# STM32U375 register map
File version: 1.0
CPU: CM33 r0p1, little endian, MPU, FPU, 4 interrupt priority bits
Registers are 32-bit, read-write, reset 0x0 unless marked. A register's access mark holds for its fields unless they carry their own. Offsets are from the block's base; [hi:lo] are bit positions; {n}, {i} and the like mark numbered series; 'fields as' and 'values as' point back to an identical list.

## RCC — Habu_RCC register block
Base 0x40030C00
Same registers: SEC_RCC 0x50030C00
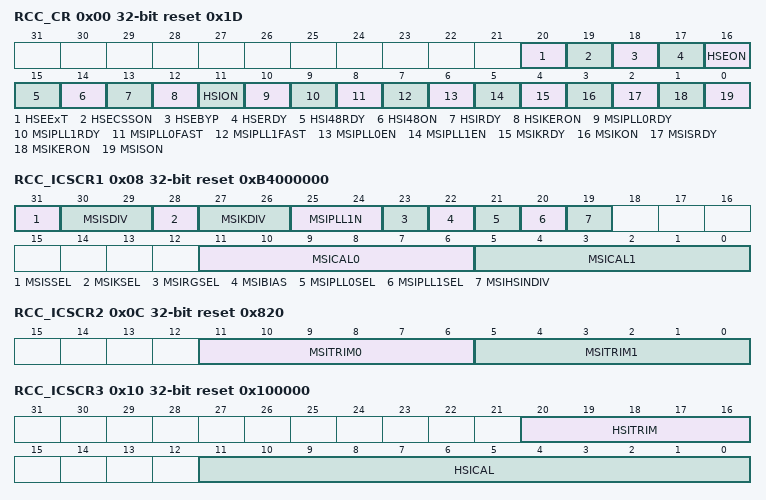
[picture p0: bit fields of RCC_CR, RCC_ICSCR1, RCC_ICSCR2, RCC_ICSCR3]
0x00 RCC_CR reset 0x1D — RCC clock control register
  [20] HSEExT — HSE external clock bypass mode
    0=External HSE clock analog mode; 1=External HSE clock digital mode (through I/O Schmitt trigger)
  [19] HSECSSON — Clock security system enable
    0=Clock security system OFF (clock detector OFF); 1=Clock security system ON (clock detector ON if the HSE oscillator is stable, OFF if not)
  [18] HSEBYP — HSE crystal oscillator bypass
    0=HSE crystal oscillator not bypassed; 1=HSE crystal oscillator bypassed with external clock
  [17] HSERDY ro — HSE clock ready flag
    0=HSE oscillator not ready; 1=HSE oscillator ready
  [16] HSEON — HSE clock enable
    0=HSE oscillator OFF; 1=HSE oscillator ON
  [15] HSI48RDY ro — HSI48 clock ready flag
    0=HSI48 oscillator not ready; 1=HSI48 oscillator ready
  [14] HSI48ON — HSI48 clock enable
    0=HSI48 oscillator OFF; 1=HSI48 oscillator ON
  [13] HSIRDY ro — HSI16 clock ready flag
    0=HSI16 oscillator not ready; 1=HSI16 oscillator ready
  [12] HSIKERON — HSI16 enable for some peripheral kernels
    0=No effect on HSI16 oscillator; 1=HSI16 oscillator forced ON even in Stop mode
  [11] HSION — HSI16 clock enable
    0=HSI16 oscillator OFF; 1=HSI16 oscillator ON
  [10] MSIPLL0RDY ro — MSIRC0 PLL mode ready flag
    0=MSIRC0 PLL mode is not ready; 1=MSIRC0 PLL mode is ready
  [9] MSIPLL1RDY ro — MSIRC1 PLL mode ready flag
    0=MSIRC1 PLL mode is not ready; 1=MSIRC1 PLL mode is ready
  [8] MSIPLL0FAST — MSIRC0 PLL mode fast startup
    0=MSIRC0 PLL normal startup; 1=MSIRC0 PLL fast startup
  [7] MSIPLL1FAST — MSIRC1 PLL mode fast startup
    0=MSIRC1 PLL normal startup; 1=MSIRC1 PLL fast startup
  [6] MSIPLL0EN — MSIRC0 PLL mode enable
    0=MSIRC0 PLL mode disabled; 1=MSIRC0 PLL mode enabled
  [5] MSIPLL1EN — MSIRC1 PLL mode enable
    0=MSIRC1 PLL mode disabled; 1=MSIRC1 PLL mode enabled
  [4] MSIKRDY ro — MSIK clock ready flag
    0=MSIK (MSI kernel) oscillator not ready; 1=MSIK (MSI kernel) oscillator ready
  [3] MSIKON — MSIK clock enable
    0=MSIK (MSI kernel) oscillator disabled; 1=MSIK (MSI kernel) oscillator enabled
  [2] MSISRDY ro — MSIS clock ready flag
    0=MSIS (MSI system) oscillator not ready; 1=MSIS (MSI system) oscillator ready
  [1] MSIKERON — MSI enable for some peripheral kernels
    0=No effect on MSI oscillator; 1=MSI oscillator forced ON even in Stop mode
  [0] MSISON — MSIS clock enable
    0=MSIS (MSI system) oscillator OFF; 1=MSIS (MSI system) oscillator ON
0x08 RCC_ICSCR1 reset 0xB4000000 (reset mask 0xFFFFF000) — RCC internal clock source calibration register 1
  [31] MSISSEL — MSIS clock source selection
    0=MSIRC0 (96 MHz) is selected as source to generate MSIS; 1=MSIRC1 (24 MHz) is selected as source to generate MSIS
  [30:29] MSISDIV — MSIS oscillator division
    0=B_0x0_MSISSEL_BIT_IN_RCC_ICSCR1__EQUAL_0 (MSIRC0/1 is selected for MSIS (range 0 around 96 MHz).); 1=B_0x1_MSISSEL_BIT_IN_RCC_ICSCR1__EQUAL_0 (MSIRC0/2 is selected for MSIS (range 1 around 48 MHz).); 2=B_0x2_MSISSEL_BIT_IN_RCC_ICSCR1__EQUAL_0 (MSIRC0/4 is selected for MSIS (range 2 around 24 MHz).); 3=B_0x3_MSISSEL_BIT_IN_RCC_ICSCR1__EQUAL_0 (MSIRC0/8 is selected for MSIS (range 3 around 12 MHz).)
  [28] MSIKSEL — MSIK clock source selection
    0=MSIRC0 (96 MHz) is selected as source to generate MSIK; 1=MSIRC1 (24 MHz) is selected as source to generate MSIK
  [27:26] MSIKDIV — MSIK oscillator division
    0=B_0x0_MSIKSEL_BIT_IN_RCC_ICSCR1__EQUAL_0 (MSIRC0/1 is selected for MSIK (range 0 around 96 MHz).); 1=B_0x1_MSIKSEL_BIT_IN_RCC_ICSCR1__EQUAL_0 (MSIRC0/2 is selected for MSIK (range 1 around 48 MHz).); 2=B_0x2_MSIKSEL_BIT_IN_RCC_ICSCR1__EQUAL_0 (MSIRC0/4 is selected for MSIK (range 2 around 24 MHz).); 3=B_0x3_MSIKSEL_BIT_IN_RCC_ICSCR1__EQUAL_0 (MSIRC0/8 is selected for MSIK (range 3 around 12 MHz).)
  [25:24] MSIPLL1N — MSIRC1 PLL mode with LSE multiplication factor
  [23] MSIRGSEL — MSI clock range selection
    0=MSIS/MSIK ranges provided by MSISDIVS[1:0] and MSIKDIVS[1:0] in RCC_CSR; 1=MSIS/MSIK ranges provided by MSISDIV[1:0] and MSIKDIV[1:0] in RCC_ICSCR1
  [22] MSIBIAS — MSI bias mode selection
    0=MSI bias continuous mode (clock accuracy fast settling time); 1=MSI bias sampling mode when the device is in Stop 1 or Stop 2 mode, or when the regulator is in range 2
  [21] MSIPLL0SEL — MSIRC0 PLL mode input clock selection
    0=LSE is used as MSIRC0 input clock when PLL mode is selected; 1=HSE or HSE/2 is used as MSIRC0 input clock when PLL mode is selected
  [20] MSIPLL1SEL — MSIRC1 PLL mode input clock selection
    0=LSE is used as MSIRC1 input clock when PLL mode is selected; 1=HSE or HSE/2 is used as MSIRC1 input clock when PLL mode is selected
  [19] MSIHSINDIV — MSIRCx (x = 0, 1) PLL mode HSE input division
    0=HSE (16 MHz) is used as MSI input clock when PLL mode with high-speed clock is selected; 1=HSE (32 MHz)/2 is used as MSI input clock when PLL mode with high-speed clock is selected
  [11:6] MSICAL0 ro — MSIRC0 clock calibration for MSI ranges 0 to 3
  [5:0] MSICAL1 ro — MSIRC1 clock calibration for MSI ranges 4 to 7
0x0C RCC_ICSCR2 reset 0x820 — RCC internal clock source calibration register 2
  [11:6] MSITRIM0 — MSIRC0 clock trimming for ranges 0 to 3
  [5:0] MSITRIM1 — MSIRC1 clock trimming for ranges 4 to 7
0x10 RCC_ICSCR3 reset 0x100000 (reset mask 0xFFFFF000) — RCC internal clock source calibration register 3
  [20:16] HSITRIM — HSI clock trimming
  [11:0] HSICAL ro — HSI clock calibration
0x14 RCC_CRRCR ro (reset mask 0xFFFFF000) — RCC clock recovery RC register
  [8:0] HSI48CAL — HSI48 clock calibration
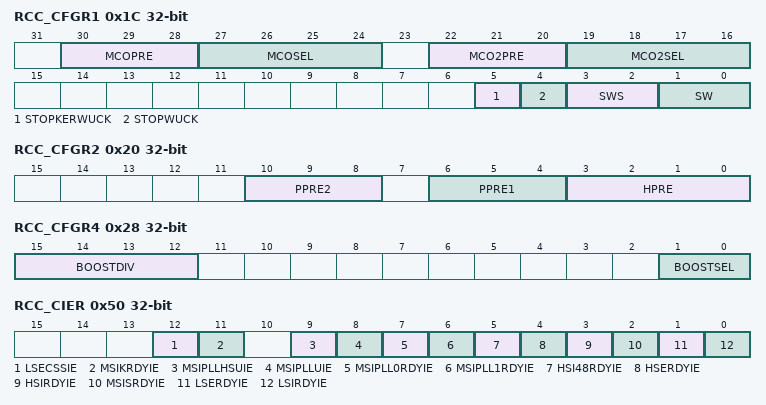
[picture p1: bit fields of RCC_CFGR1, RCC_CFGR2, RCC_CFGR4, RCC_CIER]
0x1C RCC_CFGR1 — RCC clock configuration register 1
  [30:28] MCOPRE — Microcontroller clock output prescaler
    0=MCO divided by 1; 1=MCO divided by 2; 2=MCO divided by 4; 3=MCO divided by 8; 4=MCO divided by 16; 5=MCO divided by 32; 6=MCO divided by 64; 7=MCO divided by 128
  [27:24] MCOSEL — Microcontroller clock output
    0=MCO output disabled, no clock on MCO; 1=SYSCLK system clock selected; 2=MSIS clock selected; 3=HSI16 clock selected; 4=HSE clock selected; 5=LSI clock selected; 6=LSE clock selected; 7=HSI48 clock selected; 8=MSIK clock selected
  [22:20] MCO2PRE — Microcontroller clock output 2 prescaler
    0=MCO2 divided by 1; 1=MCO2 divided by 2; 2=MCO2 divided by 4; 3=MCO2 divided by 8; 4=MCO2 divided by 16; 5=MCO2 divided by 32; 6=MCO2 divided by 64; 7=MCO2 divided by 128
  [19:16] MCO2SEL — Microcontroller clock output 2
    0=MCO2 output disabled, no clock on MCO2; 1=SYSCLK system clock selected; 2=MSIS clock selected; 3=HSI16 clock selected; 4=HSE clock selected 0101: LSI clock selected; 6=LSE clock selected; 7=HSI48 clock selected; 8=MSIK clock selected
  [5] STOPKERWUCK — Wake-up from Stop kernel clock automatic enable selection
    0=MSIK oscillator automatically enabled when exiting Stop mode or when a CSS on HSE event occurs; 1=HSI16 oscillator automatically enabled when exiting Stop mode or when a CSS on HSE event occurs
  [4] STOPWUCK — Wake-up from Stop and CSS backup clock selection
    0=MSIS oscillator selected as wake-up from stop clock and CSS backup clock; 1=HSI16 oscillator selected as wake-up from stop clock and CSS backup clock
  [3:2] SWS ro — System clock switch status
    0=MSIS oscillator used as system clock; 1=HSI16 oscillator used as system clock; 2=HSE used as system clock
  [1:0] SW — System clock switch
    0=MSIS selected as system clock; 1=HSI16 selected as system clock; 2=HSE selected as system clock
0x20 RCC_CFGR2 — RCC clock configuration register 2
  [10:8] PPRE2 — APB2 prescaler
    {v}=PCLK2 = HCLK not divided (v=0..3); 4=PCLK2 = HCLK divided by 2; 5=PCLK2 = HCLK divided by 4; 6=PCLK2 = HCLK divided by 8; 7=PCLK2 = HCLK divided by 16
  [6:4] PPRE1 — APB1 prescaler
    {v}=PCLK1 = HCLK not divided (v=0..3); 4=PCLK1 = HCLK divided by 2; 5=PCLK1 = HCLK divided by 4; 6=PCLK1 = HCLK divided by 8; 7=PCLK1 = HCLK divided by 16
  [3:0] HPRE — AHB prescaler
    {v}=HCLK = SYSCLK not divided (v=0..7); 8=HCLK = SYSCLK divided by 2; 9=HCLK = SYSCLK divided by 4; 10=HCLK = SYSCLK divided by 8; 11=HCLK = SYSCLK divided by 16; 12=HCLK = SYSCLK divided by 64; 13=HCLK = SYSCLK divided by 128; 14=HCLK = SYSCLK divided by 256; 15=HCLK = SYSCLK divided by 512
0x24 RCC_CFGR3 — RCC clock configuration register 3
  [6:4] PPRE3 — APB3 prescaler
    {v}=PCLK3 = HCLK not divided (v=0..3); 4=PCLK3 = HCLK divided by 2; 5=PCLK3 = HCLK divided by 4; 6=PCLK3 = HCLK divided by 8; 7=PCLK3 = HCLK divided by 16
0x28 RCC_CFGR4 — RCC clock configuration register 4
  [15:12] BOOSTDIV — EPOD booster input clock prescaler
    0=Divided by 1 (bypass); 1=Divided by 2; 2=Divided by 4; 3=Divided by 6; 4=Divided by 8; 5=Divided by 10; 6=Divided by 12; 7=Divided by 14; 8=Divided by 16
  [1:0] BOOSTSEL — EPOD booster input clock source selection
    0=No clock; 1=MSIS selected as EPOD booster clock source; 2=HSI16 selected as EPOD booster clock source; 3=HSE selected as EPOD booster clock source
0x50 RCC_CIER — RCC clock interrupt enable register
  [12] LSECSSIE — LSE clock security system interrupt enable
    0=LSE CSS interrupt disabled; 1=LSE CSS interrupt enabled
  [11] MSIKRDYIE — MSIK ready interrupt enable
    0=MSIK ready interrupt disabled; 1=MSIK ready interrupt enabled
  [9] MSIPLLHSUIE — MSI PLL mode with HSE unlock interrupt enable
    0=MSI PLL mode with HSE unlock interrupt disabled; 1=MSI PLL mode with HSE unlock interrupt enabled
  [8] MSIPLLUIE — MSI PLL mode with LSE unlock interrupt enable
    0=MSI PLL mode with LSE unlock interrupt disabled; 1=MSI PLL mode with LSE unlock interrupt enabled
  [7] MSIPLL0RDYIE — MSIRC0 PLL mode ready interrupt enable
    0=MSIRC0 PLL mode lock interrupt disabled; 1=MSIRC0 PLL mode lock interrupt enabled
  [6] MSIPLL1RDYIE — MSIRC1 PLL mode ready interrupt enable
    0=MSIRC1 PLL mode lock interrupt disabled; 1=MSIRC1 PLL mode lock interrupt enabled
  [5] HSI48RDYIE — HSI48 ready interrupt enable
    0=HSI48 ready interrupt disabled; 1=HSI48 ready interrupt enabled
  [4] HSERDYIE — HSE ready interrupt enable
    0=HSE ready interrupt disabled; 1=HSE ready interrupt enabled
  [3] HSIRDYIE — HSI16 ready interrupt enable
    0=HSI16 ready interrupt disabled; 1=HSI16 ready interrupt enabled
  [2] MSISRDYIE — MSIS ready interrupt enable
    0=MSIS ready interrupt disabled; 1=MSIS ready interrupt enabled
  [1] LSERDYIE — LSE ready interrupt enable
    0=LSE ready interrupt disabled; 1=LSE ready interrupt enabled
  [0] LSIRDYIE — LSI ready interrupt enable
    0=LSI ready interrupt disabled; 1=LSI ready interrupt enabled
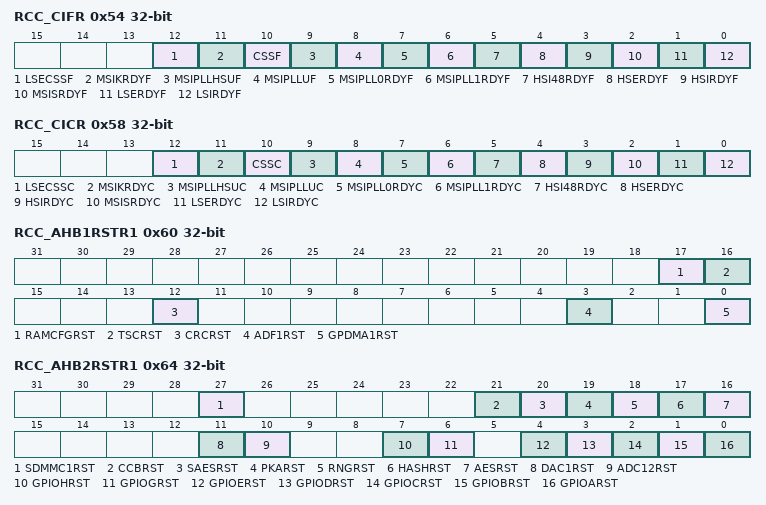
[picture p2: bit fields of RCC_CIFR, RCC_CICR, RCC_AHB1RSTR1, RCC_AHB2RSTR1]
0x54 RCC_CIFR ro — RCC clock interrupt flag register
  [12] LSECSSF — LSE clock security system interrupt flag
    0=No LSE clock security interrupt; 1=LSE clock security interrupt
  [11] MSIKRDYF — MSIK ready interrupt flag
    0=No MSIK oscillator clock ready interrupt; 1=MSIK oscillator clock ready interrupt
  [10] CSSF — Clock security system interrupt flag
    0=No HSE clock security interrupt; 1=HSE clock security interrupt
  [9] MSIPLLHSUF — MSI PLL mode with HSE unlock interrupt flag
    0=No MSI PLL mode with HSE unlock interrupt; 1=MSI PLL mode with HSE unlock interrupt
  [8] MSIPLLUF — MSI PLL mode with LSE unlock interrupt flag
    0=No MSI PLL mode with LSE unlock interrupt; 1=MSI PLL mode with LSE unlock interrupt
  [7] MSIPLL0RDYF — MSIRC0 PLL mode ready interrupt flag
    0=No MSIRC0 PLL mode ready interrupt; 1=MSIRC0 PLL mode ready interrupt
  [6] MSIPLL1RDYF — MSIRC1 PLL mode ready interrupt enable
    0=No MSIRC1 PLL mode ready interrupt; 1=MSIRC1 PLL mode ready interrupt
  [5] HSI48RDYF — HSI48 ready interrupt flag
    0=No HSI48 ready interrupt; 1=HSI48 ready interrupt
  [4] HSERDYF — HSE ready interrupt flag
    0=No HSE ready interrupt; 1=HSE ready interrupt
  [3] HSIRDYF — HSI16 ready interrupt flag
    0=No HSI16 ready interrupt; 1=HSI16 ready interrupt
  [2] MSISRDYF — MSIS ready interrupt flag
    0=No MSIS ready interrupt; 1=MSIS ready interrupt
  [1] LSERDYF — LSE ready interrupt flag
    0=No LSE ready interrupt; 1=LSE ready interrupt
  [0] LSIRDYF — LSI ready interrupt flag
    0=No LSI ready interrupt; 1=LSI ready interrupt
0x58 RCC_CICR wo — RCC clock interrupt clear register
  [12] LSECSSC — LSE CSS interrupt clear
  [11] MSIKRDYC — MSIK oscillator ready interrupt clear
  [10] CSSC — Clock security system interrupt clear
  [9] MSIPLLHSUC — MSI PLL mode with HSE unlock interrupt clear
  [8] MSIPLLUC — MSI PLL mode with LSE unlock interrupt clear
  [7] MSIPLL0RDYC — MSIRC0 PLL mode ready interrupt clear
  [6] MSIPLL1RDYC — MSIRC1 PLL mode ready interrupt clear
  [5] HSI48RDYC — HSI48 ready interrupt clear
  [4] HSERDYC — HSE ready interrupt clear
  [3] HSIRDYC — HSI16 ready interrupt clear
  [2] MSISRDYC — MSIS ready interrupt clear
  [1] LSERDYC — LSE ready interrupt clear
  [0] LSIRDYC — LSI ready interrupt clear
0x60 RCC_AHB1RSTR1 — RCC AHB1 peripheral reset register 1
  [17] RAMCFGRST — RAMCFG reset
    0=No effect; 1=Reset RAMCFG
  [16] TSCRST — TSC reset
    0=No effect; 1=Reset TSC
  [12] CRCRST — CRC reset
    0=No effect; 1=Reset CRC
  [3] ADF1RST — ADF1 reset
    0=No effect; 1=Reset ADF1
  [0] GPDMA1RST — GPDMA1 reset
    0=No effect; 1=Reset GPDMA1
0x64 RCC_AHB2RSTR1 — RCC AHB2 peripheral reset register 1
  [27] SDMMC1RST — SDMMC1 reset
    0=No effect; 1=Reset SDMMC1
  [21] CCBRST — CCB reset
    0=No effect; 1=Reset CCB
  [20] SAESRST — SAES hardware accelerator reset
    0=No effect; 1=Reset SAES
  [19] PKARST — PKA reset
    0=No effect; 1=Reset PKA
  [18] RNGRST — Random number generator reset
    0=No effect; 1=Reset RNG
  [17] HASHRST — HASH reset
    0=No effect; 1=Reset HASH
  [16] AESRST — AES hardware accelerator reset
    0=No effect; 1=Reset AES
  [11] DAC1RST — DAC1 reset
    0=No effect; 1=Reset DAC1
  [10] ADC12RST — ADC12 reset
    0=No effect; 1=Reset ADC12
  [7] GPIOHRST — I/O port i reset (i = H to G)
    0=No effect; 1=Reset I/O port i
  [6] GPIOGRST — I/O port i reset (i = H to G)
    0=No effect; 1=Reset I/O port i
  [4] GPIOERST — I/O port i reset (i = E to A)
    0=No effect; 1=Reset I/O port i
  [3] GPIODRST — I/O port i reset (i = E to A)
    0=No effect; 1=Reset I/O port i
  [2] GPIOCRST — I/O port i reset (i = E to A)
    0=No effect; 1=Reset I/O port i
  [1] GPIOBRST — I/O port i reset (i = E to A)
    0=No effect; 1=Reset I/O port i
  [0] GPIOARST — I/O port i reset (i = E to A)
    0=No effect; 1=Reset I/O port i
0x68 RCC_AHB2RSTR2 — RCC AHB2 peripheral reset register 2
  [4] OCTOSPI1RST — OCTOSPI1 reset
    0=No effect; 1=Reset OCTOSPI1
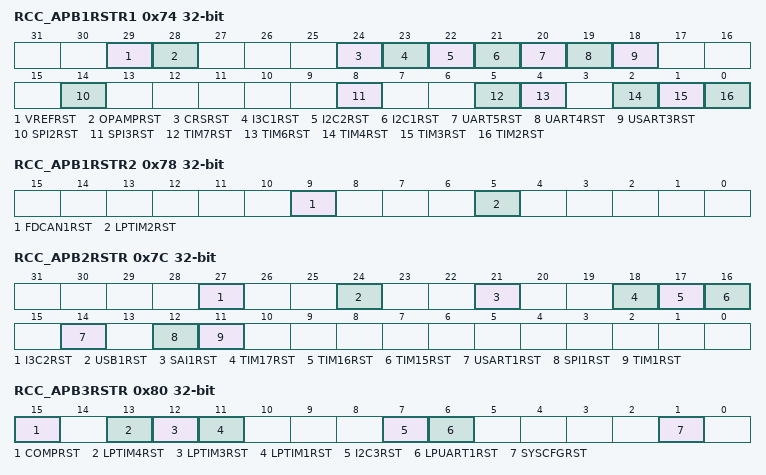
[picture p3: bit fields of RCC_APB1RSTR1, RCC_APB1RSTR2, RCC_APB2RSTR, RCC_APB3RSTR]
0x74 RCC_APB1RSTR1 — RCC APB1 peripheral reset register 1
  [29] VREFRST — VREFBUF reset
    0=No effect; 1=Reset VREFBUF
  [28] OPAMPRST — OPAMP reset
    0=No effect; 1=Reset OPAMP
  [24] CRSRST — CRS reset
    0=No effect; 1=Reset the CRS
  [23] I3C1RST — I3C1 reset
    0=No effect; 1=Reset the I3C1
  [22] I2C2RST — I2C2 reset
    0=No effect; 1=Reset the I2C2
  [21] I2C1RST — I2C1 reset
    0=No effect; 1=Reset the I2C1
  [20] UART5RST — UART5 reset
    0=No effect; 1=Reset UART5
  [19] UART4RST — UART4 reset
    0=No effect; 1=Reset UART4
  [18] USART3RST — USART3 reset
    0=No effect; 1=Reset USART3
  [14] SPI2RST — SPI2 reset
    0=No effect; 1=Reset SPI2
  [8] SPI3RST — SPI3 reset
    0=No effect; 1=Reset SPI3
  [5] TIM7RST — TIMj reset
    0=No effect; 1=Reset TIMj
  [4] TIM6RST — TIMj reset
    0=No effect; 1=Reset TIMj
  [2] TIM4RST — TIMj reset
    0=No effect; 1=Reset TIMj
  [1] TIM3RST — TIMj reset
    0=No effect; 1=Reset TIMj
  [0] TIM2RST — TIMj reset
    0=No effect; 1=Reset TIMj
0x78 RCC_APB1RSTR2 — RCC APB1 peripheral reset register 2
  [9] FDCAN1RST — FDCAN1 reset
    0=No effect; 1=Reset FDCAN1
  [5] LPTIM2RST — LPTIM2 reset
    0=No effect; 1=Reset LPTIM2
0x7C RCC_APB2RSTR — RCC APB2 peripheral reset register
  [27] I3C2RST — I3C2 reset
    0=No effect; 1=Reset I3C2
  [24] USB1RST — USB1 reset
    0=No effect; 1=Reset USB1
  [21] SAI1RST — SAI1 reset
    0=No effect; 1=Reset SAI1
  [18] TIM17RST — TIMi reset
    0=No effect; 1=Reset TIMi
  [17] TIM16RST — TIMi reset
    0=No effect; 1=Reset TIMi
  [16] TIM15RST — TIMi reset
    0=No effect; 1=Reset TIMi
  [14] USART1RST — USART1 reset
    0=No effect; 1=Reset USART1
  [12] SPI1RST — SPI1 reset
    0=No effect; 1=Reset SPI1
  [11] TIM1RST — TIM1 reset
    0=No effect; 1=Reset TIM1
0x80 RCC_APB3RSTR — RCC APB3 peripheral reset register
  [15] COMPRST — COMP reset
    0=No effect; 1=Reset COMP
  [13] LPTIM4RST — LPTIMi reset
    0=No effect; 1=Reset LPTIMi
  [12] LPTIM3RST — LPTIMi reset
    0=No effect; 1=Reset LPTIMi
  [11] LPTIM1RST — LPTIM1 reset
    0=No effect; 1=Reset LPTIM1
  [7] I2C3RST — I2C3 reset
    0=No effect; 1=Reset I2C3
  [6] LPUART1RST — LPUART1 reset
    0=No effect; 1=Reset LPUART1
  [1] SYSCFGRST — SYSCFG reset
    0=No effect; 1=Reset SYSCFG
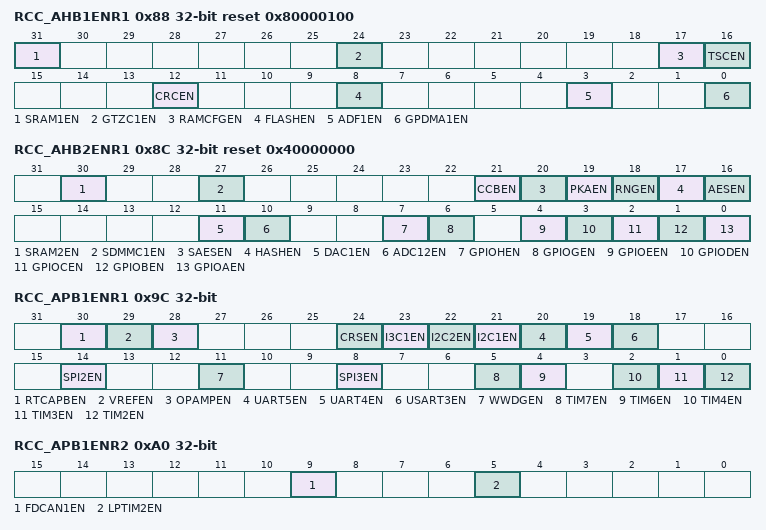
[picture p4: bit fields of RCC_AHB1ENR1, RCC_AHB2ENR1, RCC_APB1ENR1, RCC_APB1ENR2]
0x88 RCC_AHB1ENR1 reset 0x80000100 — RCC AHB1 peripheral clock enable register 1
  [31] SRAM1EN — SRAM1 clock enable
    0=SRAM1 clock disabled; 1=SRAM1 clock enabled
  [24] GTZC1EN — GTZC1 clock enable
    0=GTZC1 clock disabled; 1=GTZC1 clock enabled
  [17] RAMCFGEN — RAMCFG clock enable
    0=RAMCFG clock disabled; 1=RAMCFG clock enabled
  [16] TSCEN — Touch sensing controller clock enable
    0=TSC clock disabled; 1=TSC clock enabled
  [12] CRCEN — CRC clock enable
    0=CRC clock disabled; 1=CRC clock enabled
  [8] FLASHEN — FLASH clock enable
    0=FLASH clock disabled; 1=FLASH clock enabled
  [3] ADF1EN — ADF1 clock enable
    0=ADF1 clock disabled; 1=ADF1 clock enabled
  [0] GPDMA1EN — GPDMA1 clock enable
    0=GPDMA1 clock disabled; 1=GPDMA1 clock enabled
0x8C RCC_AHB2ENR1 reset 0x40000000 — RCC AHB2 peripheral clock enable register 1
  [30] SRAM2EN — SRAM2 clock enable
    0=SRAM2 clock disabled; 1=SRAM2 clock enabled
  [27] SDMMC1EN — SDMMC1 clock enable
    0=SDMMC1 clock disabled; 1=SDMMC1 clock enabled
  [21] CCBEN — CCB clock enable
    0=CCB clock disabled; 1=CCB clock enabled
  [20] SAESEN — SAES clock enable
    0=SAES clock disabled; 1=SAES clock enabled
  [19] PKAEN — PKA clock enable
    0=PKA clock disabled; 1=PKA clock enabled
  [18] RNGEN — RNG clock enable
    0=RNG clock disabled; 1=RNG clock enabled
  [17] HASHEN — HASH clock enable
    0=HASH clock disabled; 1=HASH clock enabled
  [16] AESEN — AES clock enable
    0=AES clock disabled; 1=AES clock enabled
  [11] DAC1EN — DAC1 clock enable
    0=DAC1 clock disabled; 1=DAC1 clock enabled
  [10] ADC12EN — ADC12 clock enable
    0=ADC12 clock disabled; 1=ADC12 clock enabled
  [7] GPIOHEN — I/O port i clock enable (i = H to G)
    0=I/O port i clock disabled; 1=I/O port i clock enabled
  [6] GPIOGEN — I/O port i clock enable (i = H to G)
    0=I/O port i clock disabled; 1=I/O port i clock enabled
  [4] GPIOEEN — I/O port i clock enable (i = E to A)
    0=I/O port i clock disabled; 1=I/O port i clock enabled
  [3] GPIODEN — I/O port i clock enable (i = E to A)
    0=I/O port i clock disabled; 1=I/O port i clock enabled
  [2] GPIOCEN — I/O port i clock enable (i = E to A)
    0=I/O port i clock disabled; 1=I/O port i clock enabled
  [1] GPIOBEN — I/O port i clock enable (i = E to A)
    0=I/O port i clock disabled; 1=I/O port i clock enabled
  [0] GPIOAEN — I/O port i clock enable (i = E to A)
    0=I/O port i clock disabled; 1=I/O port i clock enabled
0x90 RCC_AHB2ENR2 — RCC AHB2 peripheral clock enable register 2
  [4] OCTOSPI1EN — OCTOSPI1 clock enable
    0=OCTOSPI1 clock disabled; 1=OCTOSPI1 clock enabled
0x94 RCC_AHB1ENR2 — RCC AHB1 peripheral clock enable register 2
  [2] PWREN — PWR clock enable
    0=PWR clock disabled; 1=PWR clock enabled
0x9C RCC_APB1ENR1 — RCC APB1 peripheral clock enable register 1
  [30] RTCAPBEN — RTC and TAMP APB clock enable
    0=RTC and TAMP APB clock disabled; 1=RTC and TAMP APB clock enabled
  [29] VREFEN — VREFBUF clock enable
    0=VREFBUF clock disabled; 1=VREFBUF clock enabled
  [28] OPAMPEN — OPAMP clock enable
    0=OPAMP clock disabled; 1=OPAMP clock enabled
  [24] CRSEN — CRS clock enable
    0=CRS clock disabled; 1=CRS clock enabled
  [23] I3C1EN — I3C1 clock enable
    0=I3C1 clock disabled; 1=I3C1 clock enabled
  [22] I2C2EN — I2C2 clock enable
    0=I2C2 clock disabled; 1=I2C2 clock enabled
  [21] I2C1EN — I2C1 clock enable
    0=I2C1 clock disabled; 1=I2C1 clock enabled
  [20] UART5EN — UART5 clock enable
    0=UART5 clocks disabled; 1=UART5 clock enabled
  [19] UART4EN — UART4 clock enable
    0=UART4 clocks disabled; 1=UART4 clock enabled
  [18] USART3EN — USART3 clock enable
    0=USART3 clocks disabled; 1=USART3 clock enabled
  [14] SPI2EN — SPI2 clock enable
    0=SPI2 clock disabled; 1=SPI2 clock enabled
  [11] WWDGEN — WWDG clock enable
    0=WWDG clock disabled; 1=WWDG clock enabled
  [8] SPI3EN — SPI3 clock enable
    0=SPI3 clock disabled; 1=SPI3 clock enabled
  [5] TIM7EN — TIMj clock enable
    0=TIMj clock disabled; 1=TIMj clock enabled
  [4] TIM6EN — TIMj clock enable
    0=TIMj clock disabled; 1=TIMj clock enabled
  [2] TIM4EN — TIMj clock enable
    0=TIMj clock disabled; 1=TIMj clock enabled
  [1] TIM3EN — TIMj clock enable
    0=TIMj clock disabled; 1=TIMj clock enabled
  [0] TIM2EN — TIMj clock enable
    0=TIMj clock disabled; 1=TIMj clock enabled
0xA0 RCC_APB1ENR2 — RCC APB1 peripheral clock enable register 2
  [9] FDCAN1EN — FDCAN1 clock enable
    0=FDCAN1 clock disabled; 1=FDCAN1 clock enabled
  [5] LPTIM2EN — LPTIM2 clock enable
    0=LPTIM2 clock disabled; 1=LPTIM2 clock enabled
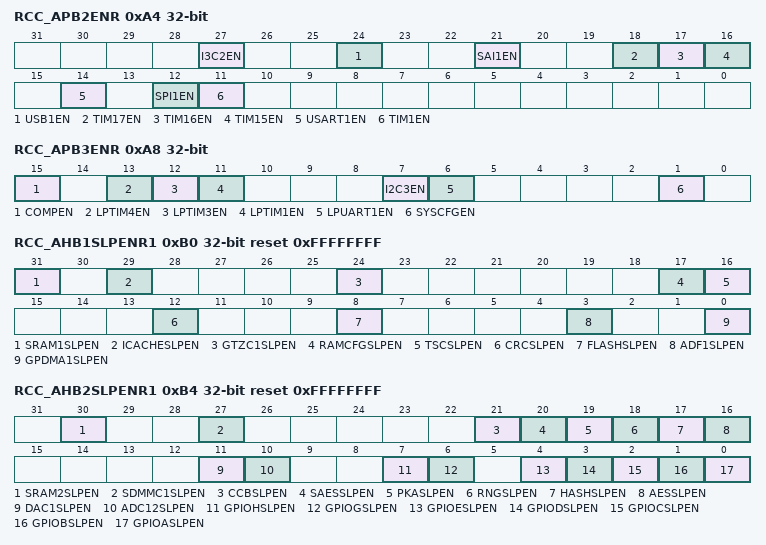
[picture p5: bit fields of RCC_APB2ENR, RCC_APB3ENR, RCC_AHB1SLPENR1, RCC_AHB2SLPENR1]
0xA4 RCC_APB2ENR — RCC APB2 peripheral clock enable register
  [27] I3C2EN — I3C2 clock enable
    0=I3C2 clock disabled; 1=I3C2 clock enabled
  [24] USB1EN — USB1 clock enable
    0=USB1 clock disabled; 1=USB1 clock enabled
  [21] SAI1EN — SAI1 clock enable
    0=SAI1 clock disabled; 1=SAI1 clock enabled
  [18] TIM17EN — TIMi clock enable
    0=TIMi clock disabled; 1=TIMi clock enabled
  [17] TIM16EN — TIMi clock enable
    0=TIMi clock disabled; 1=TIMi clock enabled
  [16] TIM15EN — TIMi clock enable
    0=TIMi clock disabled; 1=TIMi clock enabled
  [14] USART1EN — USART1clock enable
    0=USART1 clock disabled; 1=USART1 clock enabled
  [12] SPI1EN — SPI1 clock enable
    0=SPI1 clock disabled; 1=SPI1 clock enabled
  [11] TIM1EN — TIM1 clock enable
    0=TIM1 clock disabled; 1=TIM1 clock enabled
0xA8 RCC_APB3ENR — RCC APB3 peripheral clock enable register
  [15] COMPEN — COMP clock enable
    0=COMP clock disabled; 1=COMP clock enabled
  [13] LPTIM4EN — LPTIMi clock enable
    0=LPTIMi clock disabled; 1=LPTIMi clock enabled
  [12] LPTIM3EN — LPTIMi clock enable
    0=LPTIMi clock disabled; 1=LPTIMi clock enabled
  [11] LPTIM1EN — LPTIM1 clock enable
    0=LPTIM1 clock disabled; 1=LPTIM1 clock enabled
  [7] I2C3EN — I2C3 clock enable
    0=I2C3 clock disabled; 1=I2C3 clock enabled
  [6] LPUART1EN — LPUART1 clock enable
    0=LPUART1 clock disabled; 1=LPUART1 clock enabled
  [1] SYSCFGEN — SYSCFG clock enable
    0=SYSCFG clock disabled; 1=SYSCFG clock enabled
0xB0 RCC_AHB1SLPENR1 reset 0xFFFFFFFF — RCC AHB1 peripheral clock enable in Sleep mode register
  [31] SRAM1SLPEN — SRAM1 clock enable during Sleep mode
    0=SRAM1 clocks disabled by the clock gating during Sleep mode; 1=SRAM1 clock enabled by the clock gating during Sleep mode
  [29] ICACHESLPEN — ICACHE clock enable during Sleep mode
    0=ICACHE clocks disabled by the clock gating during Sleep mode; 1=ICACHE clock enabled by the clock gating during Sleep mode
  [24] GTZC1SLPEN — GTZC1 clock enable during Sleep mode
    0=GTZC1 clocks disabled by the clock gating during Sleep mode; 1=GTZC1 clock enabled by the clock gating during Sleep mode
  [17] RAMCFGSLPEN — RAMCFG clock enable during Sleep mode
    0=RAMCFG clocks disabled by the clock gating during Sleep mode; 1=RAMCFG clock enabled by the clock gating during Sleep mode
  [16] TSCSLPEN — TSC clock enable during Sleep mode
    0=TSC clocks disabled by the clock gating during Sleep mode; 1=TSC clock enabled by the clock gating during Sleep mode
  [12] CRCSLPEN — CRC clock enable during Sleep mode
    0=CRC clocks disabled by the clock gating during Sleep mode; 1=CRC clock enabled by the clock gating during Sleep mode
  [8] FLASHSLPEN — FLASH clock enable during Sleep mode
    0=FLASH clocks disabled by the clock gating during Sleep mode; 1=FLASH clock enabled by the clock gating during Sleep mode
  [3] ADF1SLPEN — ADF1 clock enable during Sleep mode.
    0=ADF1 clocks disabled by the clock gating during Sleep mode; 1=ADF1 clock enabled by the clock gating during Sleep mode
  [0] GPDMA1SLPEN — GPDMA1 clock enable during Sleep mode
    0=GPDMA1 clocks disabled by the clock gating during Sleep mode; 1=GPDMA1 clock enabled by the clock gating during Sleep mode
0xB4 RCC_AHB2SLPENR1 reset 0xFFFFFFFF — RCC AHB2 peripheral clock enable in Sleep mode register 1
  [30] SRAM2SLPEN — SRAM2 clock enable during Sleep mode
    0=SRAM2 clocks disabled by the clock gating during Sleep mode; 1=SRAM2 clock enabled by the clock gating during Sleep mode
  [27] SDMMC1SLPEN — SDMMC1 clock enable during Sleep mode
    0=SDMMC1 clocks disabled by the clock gating during Sleep mode; 1=SDMMC1 clock enabled by the clock gating during Sleep mode
  [21] CCBSLPEN — CCB accelerator clock enable during Sleep mode
    0=CCB clocks disabled by the clock gating during Sleep mode; 1=CCB clock enabled by the clock gating during Sleep mode
  [20] SAESSLPEN — SAES accelerator clock enable during Sleep mode
    0=SAES clocks disabled by the clock gating during Sleep mode; 1=SAES clock enabled by the clock gating during Sleep mode
  [19] PKASLPEN — PKA clock enable during Sleep mode
    0=PKA clocks disabled by the clock gating during Sleep mode; 1=PKA clock enabled by the clock gating during Sleep mode
  [18] RNGSLPEN — RNG clock enable during Sleep mode
    0=RNG clocks disabled by the clock gating during Sleep mode; 1=RNG clock enabled by the clock gating during Sleep mode
  [17] HASHSLPEN — HASH clock enable during Sleep mode
    0=HASH clocks disabled by the clock gating during Sleep mode; 1=HASH clock enabled by the clock gating during Sleep mode
  [16] AESSLPEN — AES clock enable during Sleep mode
    0=AES clocks disabled by the clock gating during Sleep mode; 1=AES clock enabled by the clock gating during Sleep mode
  [11] DAC1SLPEN — DAC1 clock enable during Sleep mode
    0=DAC1 clocks disabled by the clock gating during Sleep mode; 1=DAC1 clock enabled by the clock gating during Sleep mode
  [10] ADC12SLPEN — ADC12 clock enable during Sleep mode
    0=ADC12 clocks disabled by the clock gating during Sleep mode; 1=ADC12 clock enabled by the clock gating during Sleep mode
  [7] GPIOHSLPEN — I/O port i clock enable during Sleep mode (i = H to G)
    0=I/O port i clocks disabled by the clock gating during Sleep mode; 1=I/O port i clock enabled by the clock gating during Sleep mode
  [6] GPIOGSLPEN — I/O port i clock enable during Sleep mode (i = H to G)
    values as GPIOHSLPEN
  [4] GPIOESLPEN — I/O port i clock enable during Sleep mode (i = E to A)
    values as GPIOHSLPEN
  [3] GPIODSLPEN — I/O port i clock enable during Sleep mode (i = E to A)
    values as GPIOHSLPEN
  [2] GPIOCSLPEN — I/O port i clock enable during Sleep mode (i = E to A)
    values as GPIOHSLPEN
  [1] GPIOBSLPEN — I/O port i clock enable during Sleep mode (i = E to A)
    values as GPIOHSLPEN
  [0] GPIOASLPEN — I/O port i clock enable during Sleep mode (i = E to A)
    values as GPIOHSLPEN
0xB8 RCC_AHB2SLPENR2 reset 0xFFFFFFFF — RCC AHB2 peripheral clock enable in Sleep mode register 2
  [4] OCTOSPI1SLPEN — OCTOSPI1 clock enable during Sleep mode
    0=OCTOSPI1 clocks disabled by the clock gating during Sleep mode; 1=OCTOSPI1 clock enabled by the clock gating during Sleep mode
0xBC RCC_AHB1SLPENR2 reset 0xFFFFFFFF — RCC AHB1 peripheral clock enable in Sleep mode register 2
  [2] PWRSLPEN — PWR clock enable during Sleep mode
    0=PWR clock disabled by the clock gating during Sleep mode; 1=PWR clock enabled by the clock gating during Sleep mode
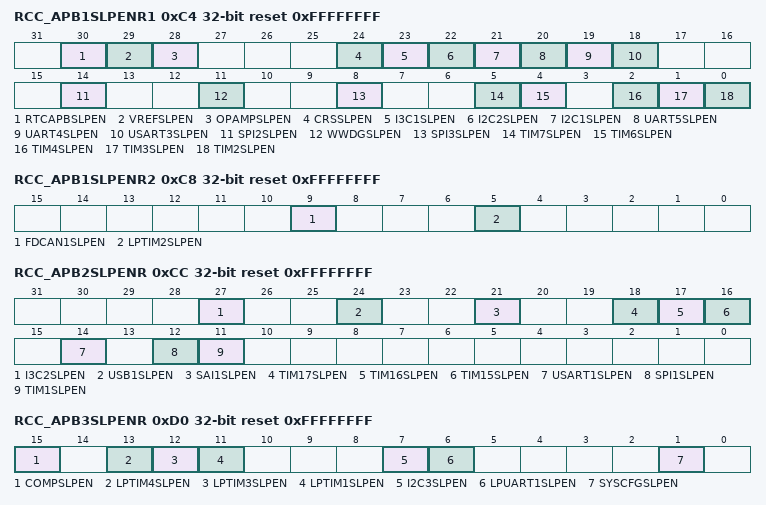
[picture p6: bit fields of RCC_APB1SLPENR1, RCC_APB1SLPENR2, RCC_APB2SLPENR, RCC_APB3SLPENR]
0xC4 RCC_APB1SLPENR1 reset 0xFFFFFFFF — RCC APB1 peripheral clock enable in Sleep mode register 1
  [30] RTCAPBSLPEN — RTC and TAMP APB clock enable during Sleep mode
    0=RTC and TAMP APB clock disabled by the clock gating during Sleep mode; 1=RTC and TAMP APB clock enabled by the clock gating during Sleep mode
  [29] VREFSLPEN — VREFBUF clock enable during Sleep mode
    0=VREFBUF clocks disabled by the clock gating during Sleep mode; 1=VREFBUF clock enabled by the clock gating during Sleep mode
  [28] OPAMPSLPEN — OPAMP clock enable during Sleep mode
    0=OPAMP clocks disabled by the clock gating during Sleep mode; 1=OPAMP clock enabled by the clock gating during Sleep mode
  [24] CRSSLPEN — CRS clock enable during Sleep mode
    0=CRS clocks disabled by the clock gating during Sleep mode; 1=CRS clock enabled by the clock gating during Sleep mode
  [23] I3C1SLPEN — I3C1 clock enable during Sleep mode
    0=I3C1 clocks disabled by the clock gating during Sleep mode; 1=I3C1 clock enabled by the clock gating during Sleep mode
  [22] I2C2SLPEN — I2C2 clock enable during Sleep mode
    0=I2C2 clocks disabled by the clock gating during Sleep mode; 1=I2C2 clock enabled by the clock gating during Sleep mode
  [21] I2C1SLPEN — I2C1 clock enable during Sleep mode
    0=I2C1 clocks disabled by the clock gating during Sleep mode; 1=I2C1 clock enabled by the clock gating during Sleep mode
  [20] UART5SLPEN — UART5 clock enable during Sleep mode
    0=UART5 clocks disabled by the clock gating during Sleep mode; 1=UART5 clock enabled by the clock gating during Sleep mode
  [19] UART4SLPEN — UART4 clock enable during Sleep mode
    0=UART4 clocks disabled by the clock gating during Sleep mode; 1=UART4 clock enabled by the clock gating during Sleep mode
  [18] USART3SLPEN — USART3 clock enable during Sleep mode
    0=USART3 clocks disabled by the clock gating during Sleep mode; 1=USART3 clock enabled by the clock gating during Sleep mode
  [14] SPI2SLPEN — SPI2 clock enable during Sleep mode
    0=SPI2 clocks disabled by the clock gating during Sleep mode; 1=SPI2 clock enabled by the clock gating during Sleep mode
  [11] WWDGSLPEN — WWDG clock enable during Sleep mode
    0=WWDG clocks disabled by the clock gating during Sleep mode; 1=WWDG clock enabled by the clock gating during Sleep mode
  [8] SPI3SLPEN — SPI3 clock enable during Sleep mode
    0=SPI3 clocks disabled by the clock gating during Sleep mode; 1=SPI3 clock enabled by the clock gating during Sleep mode
  [5] TIM7SLPEN — TIMj clock enable during Sleep mode
    0=TIMj clocks disabled by the clock gating during Sleep mode; 1=TIMj clock enabled by the clock gating during Sleep mode
  [4] TIM6SLPEN — TIMj clock enable during Sleep mode
    values as TIM7SLPEN
  [2] TIM4SLPEN — TIMj clock enable during Sleep mode
    values as TIM7SLPEN
  [1] TIM3SLPEN — TIMj clock enable during Sleep mode
    values as TIM7SLPEN
  [0] TIM2SLPEN — TIMj clock enable during Sleep mode
    values as TIM7SLPEN
0xC8 RCC_APB1SLPENR2 reset 0xFFFFFFFF — RCC APB1 peripheral clock enable in Sleep mode register 2
  [9] FDCAN1SLPEN — FDCAN1 clock enable during Sleep mode
    0=FDCAN1 clocks disabled by the clock gating during Sleep mode; 1=FDCAN1 clock enabled by the clock gating during Sleep mode
  [5] LPTIM2SLPEN — LPTIM2 clock enable during Sleep mode
    0=LPTIM2 clocks disabled by the clock gating during Sleep mode; 1=LPTIM2 clock enabled by the clock gating during Sleep mode
0xCC RCC_APB2SLPENR reset 0xFFFFFFFF — RCC APB2 peripheral clock enable in Sleep mode register
  [27] I3C2SLPEN — I3C2 clock enable during Sleep mode
    0=I3C2 clocks disabled by the clock gating during Sleep mode; 1=I3C2 clock enabled by the clock gating during Sleep mode
  [24] USB1SLPEN — USB1 clock enable during Sleep mode
    0=USB1 clocks disabled by the clock gating during Sleep mode; 1=USB1 clock enabled by the clock gating during Sleep mode
  [21] SAI1SLPEN — SAI1 clock enable during Sleep mode
    0=SAI1 clocks disabled by the clock gating during Sleep mode; 1=SAI1 clock enabled by the clock gating during Sleep mode
  [18] TIM17SLPEN — TIMi clock enable during Sleep mode
    0=TIMi clock disabled during Sleep mode; 1=TIMi clock enabled during Sleep mode
  [17] TIM16SLPEN — TIMi clock enable during Sleep mode
    values as TIM17SLPEN
  [16] TIM15SLPEN — TIMi clock enable during Sleep mode
    values as TIM17SLPEN
  [14] USART1SLPEN — USART1clock enable during Sleep mode
    0=USART1clocks disabled by the clock gating during Sleep mode; 1=USART1clock enabled by the clock gating during Sleep mode
  [12] SPI1SLPEN — SPI1 clock enable during Sleep mode
    0=SPI1 clocks disabled by the clock gating during Sleep mode; 1=SPI1 clock enabled by the clock gating during Sleep mode
  [11] TIM1SLPEN — TIM1 clock enable during Sleep mode
    0=TIM1 clock disabled during Sleep mode; 1=TIM1 clock enabled during Sleep mode
0xD0 RCC_APB3SLPENR reset 0xFFFFFFFF — RCC APB3 peripheral clock enable in Sleep mode register
  [15] COMPSLPEN — COMP clock enable during Sleep mode
    0=COMP clocks disabled by the clock gating during Sleep mode; 1=COMP clock enabled by the clock gating during Sleep mode
  [13] LPTIM4SLPEN — LPTIMi clock enable during Sleep mode
    0=LPTIMi clock disabled during Sleep mode; 1=LPTIMi clock enabled during Sleep mode
  [12] LPTIM3SLPEN — LPTIMi clock enable during Sleep mode
    values as LPTIM4SLPEN
  [11] LPTIM1SLPEN — LPTIM1clock enable during Sleep mode
    0=LPTIM1 clock disabled during Sleep mode; 1=LPTIM1 clock enabled during Sleep mode
  [7] I2C3SLPEN — I2C3 clock enable during Sleep mode
    0=I2C3 clocks disabled by the clock gating during Sleep mode; 1=I2C3 clock enabled by the clock gating during Sleep mode
  [6] LPUART1SLPEN — LPUART1 clock enable during Sleep mode
    0=LPUART1 clocks disabled by the clock gating during Sleep mode; 1=LPUART1 clock enabled by the clock gating during Sleep m
  [1] SYSCFGSLPEN — SYSCFG clock enable during Sleep mode
    0=SYSCFG clocks disabled by the clock gating during Sleep mode; 1=SYSCFG clock enabled by the clock gating during Sleep mode
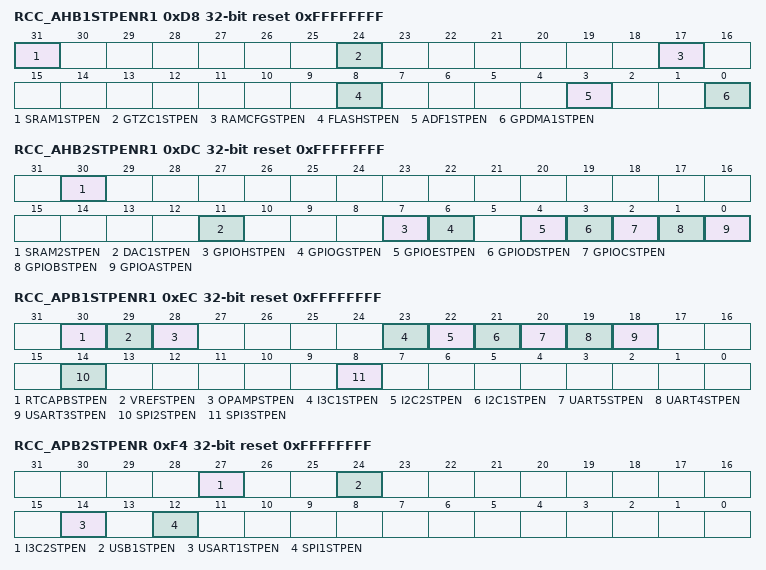
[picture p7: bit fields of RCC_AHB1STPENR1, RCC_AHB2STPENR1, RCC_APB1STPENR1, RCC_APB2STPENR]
0xD8 RCC_AHB1STPENR1 reset 0xFFFFFFFF — RCC AHB1 peripheral clock enable in Stop mode register
  [31] SRAM1STPEN — SRAM1 clock enable during Stop mode
    0=SRAM1 clocks disabled by the clock gating during Stop mode; 1=SRAM1 clock enabled by the clock gating during Stop mode
  [24] GTZC1STPEN — GTZC1 clock enable during Stop mode
    0=GTZC1 clocks disabled by the clock gating during Stop mode; 1=GTZC1 clock enabled by the clock gating during Stop mode
  [17] RAMCFGSTPEN — RAMCFG clock enable during Stop mode
    0=RAMCFG clocks disabled by the clock gating during Stop mode; 1=RAMCFG clock enabled by the clock gating during Stop mode
  [8] FLASHSTPEN — FLASH clock enable during Stop mode
    0=FLASH clocks disabled by the clock gating during Stop mode; 1=FLASH clock enabled by the clock gating during Stop mode
  [3] ADF1STPEN — ADF1 clock enable during Stop mode.
    0=ADF1 clocks disabled by the clock gating during Stop mode; 1=ADF1 clock enabled by the clock gating during Stop mode
  [0] GPDMA1STPEN — GPDMA1 clock enable during Stop mode.
    0=GPDMA1 clocks disabled by the clock gating during Stop mode; 1=GPDMA1 clock enabled by the clock gating during Stop mode
0xDC RCC_AHB2STPENR1 reset 0xFFFFFFFF — RCC AHB2 peripheral clock enable in Stop mode register 1
  [30] SRAM2STPEN — SRAM2 clock enable during Stop mode
    0=SRAM2 clocks disabled by the clock gating during Stop mode; 1=SRAM2 clock enabled by the clock gating during Stop mode
  [11] DAC1STPEN — DAC1 clock enable during Stop mode
    0=DAC1 clocks disabled by the clock gating during Stop mode; 1=DAC1 clock enabled by the clock gating during Stop mode
  [7] GPIOHSTPEN — I/O port i clock enable during Stop mode (i = H to G)
    0=I/O port i clocks disabled by the clock gating during Stop mode; 1=I/O port i clock enabled by the clock gating during Stop mode
  [6] GPIOGSTPEN — I/O port i clock enable during Stop mode (i = H to G)
    values as GPIOHSTPEN
  [4] GPIOESTPEN — I/O port i clock enable during Stop mode (i = E to A)
    values as GPIOHSTPEN
  [3] GPIODSTPEN — I/O port i clock enable during Stop mode (i = E to A)
    values as GPIOHSTPEN
  [2] GPIOCSTPEN — I/O port i clock enable during Stop mode (i = E to A)
    values as GPIOHSTPEN
  [1] GPIOBSTPEN — I/O port i clock enable during Stop mode (i = E to A)
    values as GPIOHSTPEN
  [0] GPIOASTPEN — I/O port i clock enable during Stop mode (i = E to A)
    values as GPIOHSTPEN
0xEC RCC_APB1STPENR1 reset 0xFFFFFFFF — RCC APB1 peripheral clock enable in Stop mode register 1
  [30] RTCAPBSTPEN — RTC and TAMP APB clock enable during Stop mode
    0=RTC and TAMP APB clock disabled by the clock gating during Stop mode; 1=RTC and TAMP APB clock enabled by the clock gating during Stop mode
  [29] VREFSTPEN — VREFBUF clock enable during Stop mode
    0=VREFBUF clocks disabled by the clock gating during Stop mode; 1=VREFBUF clock enabled by the clock gating during Stop mode
  [28] OPAMPSTPEN — OPAMP clock enable during Stop mode
    0=OPAMP clocks disabled by the clock gating during Stop mode; 1=OPAMP clock enabled by the clock gating during Stop mode
  [23] I3C1STPEN — I3C1 clock enable during Stop mode
    0=I3C1 clocks disabled by the clock gating during Stop mode; 1=I3C1 clock enabled by the clock gating during Stop mode
  [22] I2C2STPEN — I2C2 clock enable during Stop mode
    0=I2C2 clocks disabled by the clock gating during Stop mode; 1=I2C2 clock enabled by the clock gating during Stop mode
  [21] I2C1STPEN — I2C1 clock enable during Stop mode
    0=I2C1 clocks disabled by the clock gating during Stop mode; 1=I2C1 clock enabled by the clock gating during Stop mode
  [20] UART5STPEN — UART5 clock enable during Stop mode
    0=UART5 clocks disabled by the clock gating during Stop mode; 1=UART5 clock enabled by the clock gating during Stop mode
  [19] UART4STPEN — UART4 clock enable during Stop mode
    0=UART4 clocks disabled by the clock gating during Stop mode; 1=UART4 clock enabled by the clock gating during Stop mode
  [18] USART3STPEN — USART3 clock enable during Stop mode
    0=USART3 clocks disabled by the clock gating during Stop mode; 1=USART3 clock enabled by the clock gating during Stop mode
  [14] SPI2STPEN — SPI2 clock enable during Stop mode
    0=SPI2 clocks disabled by the clock gating during Stop mode; 1=SPI2 clock enabled by the clock gating during Stop mode
  [8] SPI3STPEN — SPI3 clock enable during Stop mode
    0=SPI3 clocks disabled by the clock gating during Stop mode; 1=SPI3 clock enabled by the clock gating during Stop mode
0xF0 RCC_APB1STPENR2 reset 0xFFFFFFFF — RCC APB1 peripheral clock enable in Stop mode register 2
  [5] LPTIM2STPEN — LPTIM2 clock enable during Stop mode
    0=LPTIM2 clocks disabled by the clock gating during Stop mode; 1=LPTIM2 clock enabled by the clock gating during Stop mode
0xF4 RCC_APB2STPENR reset 0xFFFFFFFF — RCC APB2 peripheral clock enable in Stop mode register
  [27] I3C2STPEN — I3C2 clock enable during Stop mode
    0=I3C2 clocks disabled by the clock gating during Stop mode; 1=I3C2 clock enabled by the clock gating during Stop mode
  [24] USB1STPEN — USB1 clock enable during Stop mode
    0=USB1 clocks disabled by the clock gating during Stop mode; 1=USB1 clock enabled by the clock gating during Stop mode
  [14] USART1STPEN — USART1clock enable during Stop mode
    0=USART1clocks disabled by the clock gating during Stop mode; 1=USART1clock enabled by the clock gating during Stop mode
  [12] SPI1STPEN — SPI1 clock enable during Stop mode
    0=SPI1 clocks disabled by the clock gating during Stop mode; 1=SPI1 clock enabled by the clock gating during Stop mode
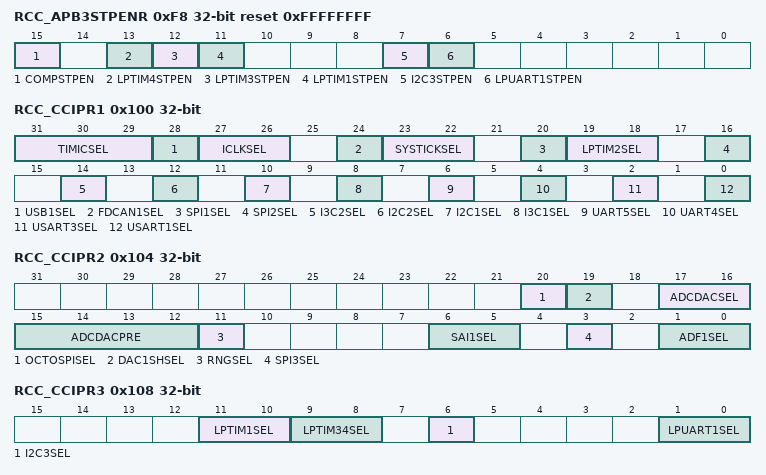
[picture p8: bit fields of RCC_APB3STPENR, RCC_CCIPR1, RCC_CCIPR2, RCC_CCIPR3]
0xF8 RCC_APB3STPENR reset 0xFFFFFFFF — RCC APB3 peripheral clock enable in Stop mode register
  [15] COMPSTPEN — COMP clock enable during Stop mode
    0=COMP clocks disabled by the clock gating during Stop mode; 1=COMP clock enabled by the clock gating during Stop mode
  [13] LPTIM4STPEN — LPTIMi clock enable during Stop mode
    0=LPTIMi clock disabled during Stop mode; 1=LPTIMi clock enabled during Stop mode
  [12] LPTIM3STPEN — LPTIMi clock enable during Stop mode
    values as LPTIM4STPEN
  [11] LPTIM1STPEN — LPTIM1clock enable during Stop mode
    0=LPTIM1 clock disabled during Stop mode; 1=LPTIM1 clock enabled during Stop mode
  [7] I2C3STPEN — I2C3 clock enable during Stop mode
    0=I2C3 clocks disabled by the clock gating during Stop mode; 1=I2C3 clock enabled by the clock gating during Stop mode
  [6] LPUART1STPEN — LPUART1 clock enable during Stop mode
    0=LPUART1 clocks disabled by the clock gating during Stop mode; 1=LPUART1 clock enabled by the clock gating during Stop m
0x100 RCC_CCIPR1 — RCC peripheral independent clock configuration register 1
  [31:29] TIMICSEL — Clock sources for TIM16,TIM17, and LPTIM2 internal input capture
    {v}=HSI, MSIK and MSIS dividers disabled (v=0..3); 4=HSI/256, MSIS/1024 and MSIS/4 are generated and can be selected by TIM16, TIM17, and LPTIM2 as internal input capture; 5=HSI/256, MSIS/1024 and MSIK/4 are generated and can be selected by TIM16, TIM17, and LPTIM2 as internal input capture; 6=HSI/256, MSIK/1024 and MSIS/4 are generated and can be selected by TIM16, TIM17, and LPTIM2 as internal input capture; 7=HSI/256, MSIK/1024 and MSIK/4 are generated and can be selected by TIM16, TIM17, and LPTIM2 as internal input capture
  [28] USB1SEL — USB1 kernel clock prescaler selection
    0=usbsdmmc_iclk selected; 1=usbsdmmc_iclk/2 selected
  [27:26] ICLKSEL — Intermediate clock source selection
    0=HSI48 selected; 1=MSIK selected; 2=HSE selected; 3=SYSCLK selected
  [24] FDCAN1SEL — FDCAN1 kernel clock source selection
    0=SYSCLK selected; 1=MSIK selected
  [23:22] SYSTICKSEL — SysTick clock source selection
    0=HCLK/8 selected; 1=LSI selected; 2=LSE selected
  [20] SPI1SEL — SPI1 kernel clock source selection
    0=PCLK2 selected; 1=MSIK selected
  [19:18] LPTIM2SEL — Low-power timer 2 kernel clock source selection
    0=PCLK1 selected; 1=LSI selected; 2=HSI16 selected; 3=LSE selected
  [16] SPI2SEL — SPI2 kernel clock source selection
    0=PCLK1 selected; 1=MSIK selected
  [14] I3C2SEL — I3C2 kernel clock source selection
    0=PCLK2 selected; 1=MSIK selected
  [12] I2C2SEL — I2C2 kernel clock source selection
    0=PCLK1 selected; 1=MSIK selected
  [10] I2C1SEL — I2C1 kernel clock source selection
    0=PCLK1 selected; 1=MSIK selected
  [8] I3C1SEL — I3C1 kernel clock source selection
    0=PCLK1 selected; 1=MSIK selected
  [6] UART5SEL — UART5 kernel clock source selection
    0=PCLK1 selected; 1=HSI16 selected
  [4] UART4SEL — UART4 kernel clock source selection
    0=PCLK1 selected; 1=HSI16 selected
  [2] USART3SEL — USART3 kernel clock source selection
    0=PCLK1 selected; 1=HSI16 selected
  [0] USART1SEL — USART1 kernel clock source selection
    0=PCLK2 selected; 1=HSI16 selected
0x104 RCC_CCIPR2 — RCC peripheral independent clock configuration register 2
  [20] OCTOSPISEL — OCTOSPI1 kernel clock source selection
    0=SYSCLK selected; 1=MSIK selected
  [19] DAC1SHSEL — DAC1 sample and hold clock source selection
    0=LSE selected; 1=LSI selected
  [17:16] ADCDACSEL — ADC12 and DAC1 intermediate kernel clock source selection
    0=HCLK selected; 1=HSE selected; 2=MSIK selected
  [15:12] ADCDACPRE — ADC12 and DAC1 kernel clock prescaler
    0=adcdac_iclk; {v}=adcdac_iclk/2 (v=1..7); 8=adcdac_iclk/4; 9=adcdac_iclk/8; 10=adcdac_iclk/16; 11=adcdac_iclk/32; 12=adcdac_iclk/64; 13=adcdac_iclk/128; 14=adcdac_iclk/256; 15=adcdac_iclk/512
  [11] RNGSEL — RNG kernel clock source selection
    0=HSI48 selected; 1=MSIK selected
  [6:5] SAI1SEL — SAI1 kernel clock source selection
    0=MSIK selected; 1=input pin AUDIOCLK selected; 2=HSE clock selected
  [3] SPI3SEL — SPI3 kernel clock source selection
    0=PCLK1 selected; 1=MSIK selected
  [1:0] ADF1SEL — ADF1 kernel clock source selection
    0=HCLK; 1=Input pin AUDIOCLK selected; 2=MSIK clock selected; 3=SAI1 kernel clock selected
0x108 RCC_CCIPR3 — RCC peripheral independent clock configuration register 3
  [11:10] LPTIM1SEL — LPTIM1 kernel clock source selection
    0=MSIK clock selected; 1=LSI selected; 2=HSI16 selected; 3=LSE selected
  [9:8] LPTIM34SEL — LPTIM3 and LPTIM4 kernel clock source selection
    values as LPTIM1SEL
  [6] I2C3SEL — I2C3 kernel clock source selection
    0=PCLK3 selected; 1=MSIK selected
  [1:0] LPUART1SEL — LPUART1 kernel clock source selection
    0=PCLK3 selected; 1=HSI16 selected; 2=LSE selected; 3=MSIK selected
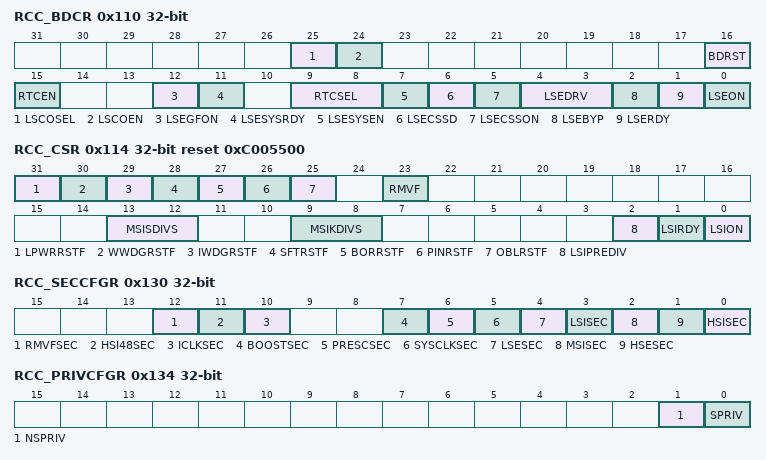
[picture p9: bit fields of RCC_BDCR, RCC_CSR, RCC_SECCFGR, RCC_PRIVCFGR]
0x110 RCC_BDCR (reset mask 0xFFFF0FFF) — RCC backup domain control register
  [25] LSCOSEL — Low-speed clock output selection
    0=LSI selected; 1=LSE selected
  [24] LSCOEN — Low-speed clock output (LSCO) enable
    0=LSCO disabled; 1=LSCO enabled
  [16] BDRST — Backup domain software reset
    0=No effec; 1=Reset the entire backup domain
  [15] RTCEN — RTC and TAMP clock enable
    0=RTC and TAMP clock disabled; 1=RTC and TAMP clock enabled
  [12] LSEGFON — LSE clock glitch filter enable
    0=LSE glitch filter disabled; 1=LSE glitch filter enabled
  [11] LSESYSRDY — LSE system clock (LSESYS) ready
    0=LSESYS clock not ready; 1=LSESYS clock ready
  [9:8] RTCSEL — RTC and TAMP clock source selection
    0=No clock selected; 1=LSE selected; 2=LSI selected; 3=HSE/32 selected
  [7] LSESYSEN — LSE system clock (LSESYS) enable
    0=LSE can be used only for RTC, TAMP, and CSS on LSE; 1=LSE can be used by any other peripheral or function
  [6] LSECSSD — CSS on LSE failure detection
    0=No failure detected on LSE; 1=Failure detected on LSE
  [5] LSECSSON — CSS on LSE enable
    0=CSS on LSE OFF; 1=CSS on LSE ON
  [4:3] LSEDRV — LSE oscillator drive capability
    0='xtal mode' lower driving capability; 1='xtal mode' medium-low driving capability; 2='xtal mode' medium-high driving capability; 3='xtal mode' higher driving capability
  [2] LSEBYP — LSE oscillator bypass
    0=LSE oscillator not bypassed
  [1] LSERDY — LSE oscillator ready
    0=LSE oscillator not ready; 1=LSE oscillator ready
  [0] LSEON — LSE oscillator enable
    0=LSE oscillator OFF; 1=LSE oscillator ON
0x114 RCC_CSR reset 0xC005500 — RCC control/status register
  [31] LPWRRSTF — Low-power reset flag
    0=No illegal low-power mode reset occurred; 1=Illegal low-power mode reset occurred
  [30] WWDGRSTF — Window watchdog reset flag
    0=No window watchdog reset occurred; 1=Window watchdog reset occurred
  [29] IWDGRSTF — Independent watchdog reset flag
    0=No independent watchdog reset occurred; 1=Independent watchdog reset occurred
  [28] SFTRSTF — Software reset flag
    0=No software reset occurred; 1=Software reset occurred
  [27] BORRSTF — BOR flag
    0=No BOR occurred; 1=BOR occurred
  [26] PINRSTF — NRST pin reset flag
    0=No reset from NRST pin occurred; 1=Reset from NRST pin occurred
  [25] OBLRSTF — Option-byte loader reset flag
    0=No reset from option-byte loading occurred; 1=Reset from option-byte loading occurred
  [23] RMVF — Remove reset flag
    0=No effect; 1=Clear the reset flags
  [13:12] MSISDIVS — MSIS oscillator division after Standby mode
    1=Range 5 around 12 MHz (reset value); 2=Range 6 around 6 MHz; 3=Range 7 around 3 MHz
  [9:8] MSIKDIVS — MSIK oscillator division after Standby mode
    values as MSISDIVS
  [2] LSIPREDIV — Low-speed clock divider configuration
    0=LSI not divided; 1=LSI divided by 128
  [1] LSIRDY — LSI oscillator ready
    0=LSI oscillator not ready; 1=LSI oscillator ready
  [0] LSION — LSI oscillator enable
    0=LSI oscillator OFF; 1=LSI oscillator ON
0x130 RCC_SECCFGR — RCC secure configuration register
  [all] fields
    0=Nonsecure; 1=Secure
  [12] RMVFSEC — Remove reset flag security
  [11] HSI48SEC — HSI48 clock configuration and status bit security
  [10] ICLKSEC — Intermediate clock source selection security
  [7] BOOSTSEC — EPOD booster configuration bit security
  [6] PRESCSEC — AHBx/APBx prescaler configuration bit security
  [5] SYSCLKSEC — SYSCLK clock selection, STOPWUCK bit, clock output on MCO configuration security
  [4] LSESEC — LSE clock configuration and status bit security
  [3] LSISEC — LSI clock configuration and status bit security
  [2] MSISEC — MSI clock configuration and status bit security
  [1] HSESEC — HSE clock configuration, status bits, and HSE_CSS security
  [0] HSISEC — HSI clock configuration and status bit security
0x134 RCC_PRIVCFGR — RCC privilege configuration register
  [1] NSPRIV — RCC nonsecure function privilege configuration
    0=Read and write to RCC nonsecure functions can be done by privileged or unprivileged access; 1=Read and write to RCC nonsecure functions can be done by privileged access only
  [0] SPRIV — RCC secure function privilege configuration
    0=Read and write to RCC secure functions can be done by privileged or unprivileged access; 1=Read and write to RCC secure functions can be done by privileged access only
